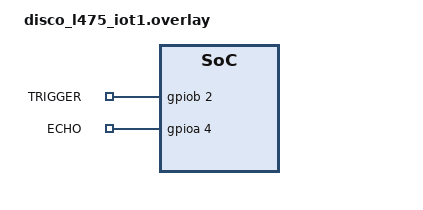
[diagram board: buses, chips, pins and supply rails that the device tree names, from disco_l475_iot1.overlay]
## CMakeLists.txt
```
cmake_minimum_required(VERSION 3.20.0)
find_package(Zephyr REQUIRED HINTS $ENV{ZEPHYR_BASE})
project(ultrasonic_node)

# Collect all .c files in this app's src/ and lib/ directories
file(GLOB app_sources ${CMAKE_CURRENT_SOURCE_DIR}/src/*.c)
file(GLOB lib_sources ${CMAKE_CURRENT_SOURCE_DIR}/lib/*.c)

# Add all sources to the app target
target_sources(app PRIVATE ${app_sources} ${lib_sources})

# Include this app's include/ and lib/ directories for header files
target_include_directories(app PRIVATE
    ${CMAKE_CURRENT_SOURCE_DIR}/include
    ${CMAKE_CURRENT_SOURCE_DIR}/lib
)
```

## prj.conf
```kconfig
# Enable Bluetooth
CONFIG_BT=y
CONFIG_BT_PERIPHERAL=y
CONFIG_BT_DEVICE_NAME="UltrasonicNode"
CONFIG_BT_DEVICE_APPEARANCE=0
CONFIG_BT_MAX_CONN=1
CONFIG_BT_BROADCASTER=y

# Serial console and logging
CONFIG_SERIAL=y
CONFIG_CONSOLE=y
CONFIG_UART_CONSOLE=y
CONFIG_PRINTK=y
CONFIG_LOG=y
CONFIG_LOG_DEFAULT_LEVEL=3
CONFIG_LOG_MODE_DEFERRED=y
CONFIG_LOG_BUFFER_SIZE=8192

# Required for GPIO access
CONFIG_GPIO=y
CONFIG_GPIO_STM32=y

# Enable floating point printing
CONFIG_NEWLIB_LIBC=y
CONFIG_NEWLIB_LIBC_FLOAT_PRINTF=y

# Enable threads
CONFIG_HEAP_MEM_POOL_SIZE=4096
```

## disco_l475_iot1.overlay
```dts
/*
 * Overlay for Ultrasonic sensor HC-SR04 on STM32L475 Discovery
 */
/ {
    ultrasonic_sensor {
        compatible = "gpio-keys";
        trigger_gpio: trigger_pin {
            label = "TRIGGER";
            gpios = <&gpiob 2 GPIO_ACTIVE_HIGH>; /* D8 */
        };
        echo_gpio: echo_pin {
            label = "ECHO";
            gpios = <&gpioa 4 GPIO_ACTIVE_HIGH>; /* D7 */
        };
    };

    aliases {
        trigger = &trigger_gpio;
        echo = &echo_gpio;
    };
};
```

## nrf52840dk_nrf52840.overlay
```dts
/*
 * Overlay for Ultrasonic sensor HC-SR04 on nRF52840 DK
 */
/ {
    ultrasonic_sensor {
        compatible = "gpio-keys";
        trigger_gpio: trigger_pin {
            label = "TRIGGER";
            gpios = <&gpio0 13 GPIO_ACTIVE_HIGH>; /* P0.13 */
        };
        echo_gpio: echo_pin {
            label = "ECHO";
            gpios = <&gpio0 11 GPIO_ACTIVE_HIGH>; /* P0.11 */
        };
    };
    aliases {
        trigger = &trigger_gpio;
        echo = &echo_gpio;
    };
};
```

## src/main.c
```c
/**
 * @file main.c
 * @brief Main application for ultrasonic sensor node with BLE communication
 */

#include <zephyr/kernel.h>
#include <zephyr/device.h>
#include <zephyr/devicetree.h>
#include <zephyr/sys/printk.h>
#include <zephyr/sys/atomic.h>
#include <zephyr/drivers/gpio.h>
#include "ultrasonic_sensor.h"
#include "ultrasonic_ble.h"

/* Using device tree aliases for trigger and echo pins */
#define TRIGGER_NODE DT_ALIAS(trigger)
#define ECHO_NODE    DT_ALIAS(echo)

/* Check if device tree nodes are enabled */
#if !DT_NODE_HAS_STATUS(TRIGGER_NODE, okay)
#error "Trigger pin not available in device tree"
#endif

#if !DT_NODE_HAS_STATUS(ECHO_NODE, okay)
#error "Echo pin not available in device tree"
#endif

/* Extract GPIO info from device tree */
#define TRIGGER_GPIO_CTLR DT_GPIO_CTLR(TRIGGER_NODE, gpios)
#define TRIGGER_PIN       DT_GPIO_PIN(TRIGGER_NODE, gpios)
#define ECHO_GPIO_CTLR    DT_GPIO_CTLR(ECHO_NODE, gpios)
#define ECHO_PIN          DT_GPIO_PIN(ECHO_NODE, gpios)

/* Ultrasonic node configuration - Change Node ID based on board */
#if defined(CONFIG_BOARD_DISCO_L475_IOT1)
  #define ULTRASONIC_NODE_ID 1  /* ID for STM32L475 Discovery node */
  #define ULTRASONIC_X_POS   0  /* Fixed X position on grid (leftmost position) */
#elif defined(CONFIG_BOARD_NRF52840DK_NRF52840)
  #define ULTRASONIC_NODE_ID 2  /* ID for nRF52840 DK node */
  #define ULTRASONIC_X_POS   0  /* Fixed X position on grid (position 1) */
#else
  #define ULTRASONIC_NODE_ID 3  /* Default ID for other boards */
  #define ULTRASONIC_X_POS   2  /* Default X position */
#endif

/* Shared state */
static atomic_t last_distance_mm = ATOMIC_INIT(0);
static atomic_t system_ready = ATOMIC_INIT(0);

int main(void)
{
    int rc;
    
    printk("=================================================\n");
    printk("Ultrasonic node starting up (Node ID: %d)\n", ULTRASONIC_NODE_ID);
    printk("Application version: 1.2.1\n");
    printk("=================================================\n");

    /* Get GPIO devices for trigger and echo pins */
    const struct device *trigger_dev = DEVICE_DT_GET(TRIGGER_GPIO_CTLR);
    const struct device *echo_dev = DEVICE_DT_GET(ECHO_GPIO_CTLR);

    printk("Trigger GPIO: %s pin %d\n", trigger_dev->name, TRIGGER_PIN);
    printk("Echo GPIO: %s pin %d\n", echo_dev->name, ECHO_PIN);

    /* Add detailed device ready checks */
    if (!device_is_ready(trigger_dev)) {
        printk("ERROR: Trigger device not ready\n");
        return -ENODEV;
    } else {
        printk("Trigger device ready\n");
    }

    if (!device_is_ready(echo_dev)) {
        printk("ERROR: Echo device not ready\n");
        return -ENODEV;
    } else {
        printk("Echo device ready\n");
    }
    
    /* Wait a moment for GPIO subsystem to fully initialize */
    k_msleep(100);

    /* Start the ultrasonic sensor thread */
    rc = ultrasonic_thread_start(trigger_dev, TRIGGER_PIN, 
                                echo_dev, ECHO_PIN,
                                &system_ready, &last_distance_mm);
    
    if (rc != 0) {
        printk("ERROR: Failed to start ultrasonic thread: %d\n", rc);
        return rc;
    }

    /* Wait for sensor system to be marked as ready with timeout */
    printk("Waiting for ultrasonic sensor to initialize...\n");
    int timeout_count = 0;
    while (atomic_get(&system_ready) == 0 && timeout_count < 50) {
        k_msleep(100);
        timeout_count++;
    }
    
    if (atomic_get(&system_ready) == 0) {
        printk("WARNING: Ultrasonic sensor initialization timed out, continuing anyway\n");
        atomic_set(&system_ready, 1);  /* Force ready state */
    } else {
        printk("Ultrasonic sensor initialized!\n");
    }

    /* Initialize BLE with retry */
    int retry = 0;
    while (retry < 3) {
        rc = ultrasonic_ble_init(ULTRASONIC_NODE_ID, ULTRASONIC_X_POS, &last_distance_mm);
        if (rc == 0) {
            break;
        }
        printk("ERROR: Failed to initialize BLE: %d (attempt %d/3)\n", rc, retry+1);
        k_msleep(500 * (retry + 1));
        retry++;
    }
    
    if (rc != 0) {
        printk("CRITICAL ERROR: BLE initialization failed after retries\n");
        return rc;
    }

    /* Start BLE broadcasting with retry */
    retry = 0;
    while (retry < 3) {
        rc = ultrasonic_ble_start_broadcasting();
        if (rc == 0) {
            break;
        }
        printk("ERROR: Failed to start BLE broadcasting: %d (attempt %d/3)\n", rc, retry+1);
        k_msleep(500 * (retry + 1));
        retry++;
    }
    
    if (rc != 0) {
        printk("CRITICAL ERROR: BLE broadcasting failed to start\n");
        return rc;
    }

    printk("Ultrasonic node fully operational!\n");

    /* Main loop for additional processing if needed */
    while (1) {
        /* Get the current distance measurement */
        uint16_t distance = get_last_distance();
        
        /* Print current distance every 5 seconds */
        printk("Current distance: %u.%03u m (%u mm)\n", 
               distance / 1000, distance % 1000, distance);
        
        k_sleep(K_SECONDS(5));
    }

    return 0;
}
```

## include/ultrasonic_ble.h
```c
/**
 * @file ultrasonic_ble.h
 * @brief BLE communication library for ultrasonic sensor node
 */

#ifndef ULTRASONIC_BLE_H
#define ULTRASONIC_BLE_H

#include <zephyr/kernel.h>
#include <zephyr/bluetooth/bluetooth.h>
#include <zephyr/bluetooth/hci.h>
#include <zephyr/sys/util.h>
#include <zephyr/sys/atomic.h>

/**
 * @brief Ultrasonic node position data
 */
struct ultrasonic_position {
    uint8_t node_id;       /* Identifier for this ultrasonic node */
    uint8_t x;             /* Fixed X position on grid (in grid units) */
    uint16_t distance_mm;  /* Distance measured by ultrasonic sensor in mm */
};

/**
 * @brief Initialize BLE for ultrasonic nodes
 * 
 * @param node_id Identifier for this ultrasonic node (1-255)
 * @param x_position Fixed X position of this node on the grid
 * @param distance_atomic Pointer to atomic variable holding the latest distance measurement
 * 
 * @return 0 on success, negative error code on failure
 */
int ultrasonic_ble_init(uint8_t node_id, uint8_t x_position, atomic_t *distance_atomic);

/**
 * @brief Start BLE advertising with ultrasonic distance data
 * 
 * This function starts a background thread that periodically broadcasts
 * the ultrasonic distance data using BLE advertising packets.
 * 
 * @return 0 on success, negative error code on failure
 */
int ultrasonic_ble_start_broadcasting(void);

/**
 * @brief Stop BLE advertising
 * 
 * @return 0 on success, negative error code on failure
 */
int ultrasonic_ble_stop_broadcasting(void);

/**
 * @brief Update the distance value to be broadcast
 * 
 * This function is typically not needed as the library automatically
 * reads from the atomic variable passed during initialization.
 * 
 * @param distance_mm New distance value in millimeters
 */
void ultrasonic_ble_update_distance(uint16_t distance_mm);

#endif /* ULTRASONIC_BLE_H */
```

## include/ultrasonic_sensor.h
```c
/**
 * @file ultrasonic_sensor.h
 * @brief HC-SR04 ultrasonic sensor driver header
 */

#ifndef ULTRASONIC_SENSOR_H
#define ULTRASONIC_SENSOR_H

#include <zephyr/kernel.h>
#include <zephyr/device.h>
#include <zephyr/devicetree.h>
#include <zephyr/drivers/gpio.h>
#include <zephyr/sys/atomic.h>

/* HC-SR04 specific constants */
#define HC_SR04_MIN_DISTANCE_MM    20    /* Minimum distance (mm) */
#define HC_SR04_MAX_DISTANCE_MM    4000  /* Maximum distance (mm) */

/**
 * @brief Initialize the HC-SR04 ultrasonic sensor
 *
 * @param trigger_dev Pointer to the trigger GPIO device
 * @param trigger_pin Trigger GPIO pin number
 * @param echo_dev Pointer to the echo GPIO device
 * @param echo_pin Echo GPIO pin number
 * @return 0 on success, negative error code on failure
 */
int hc_sr04_init(const struct device *trigger_dev, uint8_t trigger_pin,
                const struct device *echo_dev, uint8_t echo_pin);

/**
 * @brief Measure distance using HC-SR04 ultrasonic sensor
 *
 * @param trigger_dev Pointer to the trigger GPIO device
 * @param trigger_pin Trigger GPIO pin number
 * @param echo_dev Pointer to the echo GPIO device
 * @param echo_pin Echo GPIO pin number
 * @param distance_mm Pointer to store the measured distance in millimeters
 * @return 0 on success, negative error code on failure
 */
int hc_sr04_measure(const struct device *trigger_dev, uint8_t trigger_pin,
                   const struct device *echo_dev, uint8_t echo_pin,
                   uint16_t *distance_mm);

/**
 * @brief Start the ultrasonic sensor thread
 *
 * @param trigger_dev Pointer to the trigger GPIO device
 * @param trigger_pin Trigger GPIO pin number
 * @param echo_dev Pointer to the echo GPIO device
 * @param echo_pin Echo GPIO pin number
 * @param system_ready Pointer to atomic variable to signal system readiness
 * @param last_distance_mm Pointer to atomic variable to store the last measured distance
 * @return 0 on success, negative error code on failure
 */
int ultrasonic_thread_start(const struct device *trigger_dev, uint8_t trigger_pin,
                           const struct device *echo_dev, uint8_t echo_pin,
                           atomic_t *system_ready, atomic_t *last_distance_mm);

/**
 * @brief Get the last measured distance
 *
 * @return Last measured distance in millimeters
 */
uint16_t get_last_distance(void);

#endif /* ULTRASONIC_SENSOR_H */
```
